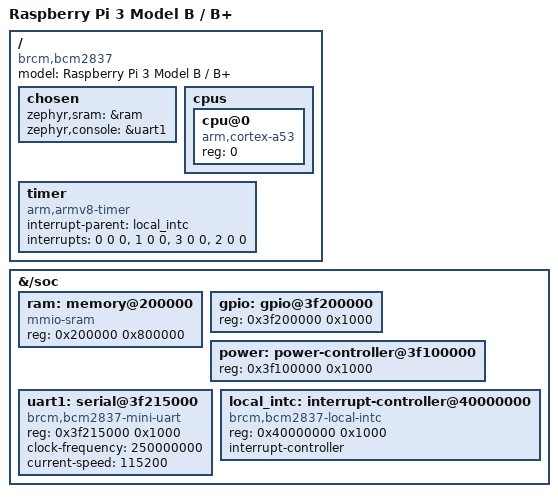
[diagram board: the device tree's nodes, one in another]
/* SPDX-License-Identifier: Apache-2.0 */
/dts-v1/;

#include <arm64/armv8-a.dtsi>

/ {
	model = "Raspberry Pi 3 Model B / B+";
	compatible = "brcm,bcm2837";

	chosen {
		zephyr,sram = &ram;
		zephyr,console = &uart1;
	};

	cpus {
		#address-cells = <1>;
		#size-cells = <0>;

		cpu@0 {
			device_type = "cpu";
			compatible = "arm,cortex-a53";
			reg = <0>;
		};
	};

	timer {
		compatible = "arm,armv8-timer";
		interrupt-parent = <&local_intc>;
		/* Secure physical, non-secure physical, virtual, hypervisor. */
		interrupts = <0 0 0>, <1 0 0>, <3 0 0>, <2 0 0>;
	};
};

&{/soc} {
	ram: memory@200000 {
		compatible = "mmio-sram";
		device_type = "memory";
		reg = <0x200000 0x800000>;
	};

	gpio: gpio@3f200000 {
		reg = <0x3f200000 0x1000>;
	};

	power: power-controller@3f100000 {
		reg = <0x3f100000 0x1000>;
	};

	uart1: serial@3f215000 {
		compatible = "brcm,bcm2837-mini-uart";
		reg = <0x3f215000 0x1000>;
		clock-frequency = <250000000>;
		current-speed = <115200>;
	};

	local_intc: interrupt-controller@40000000 {
		compatible = "brcm,bcm2837-local-intc";
		reg = <0x40000000 0x1000>;
		interrupt-controller;
		#interrupt-cells = <3>;
	};
};
